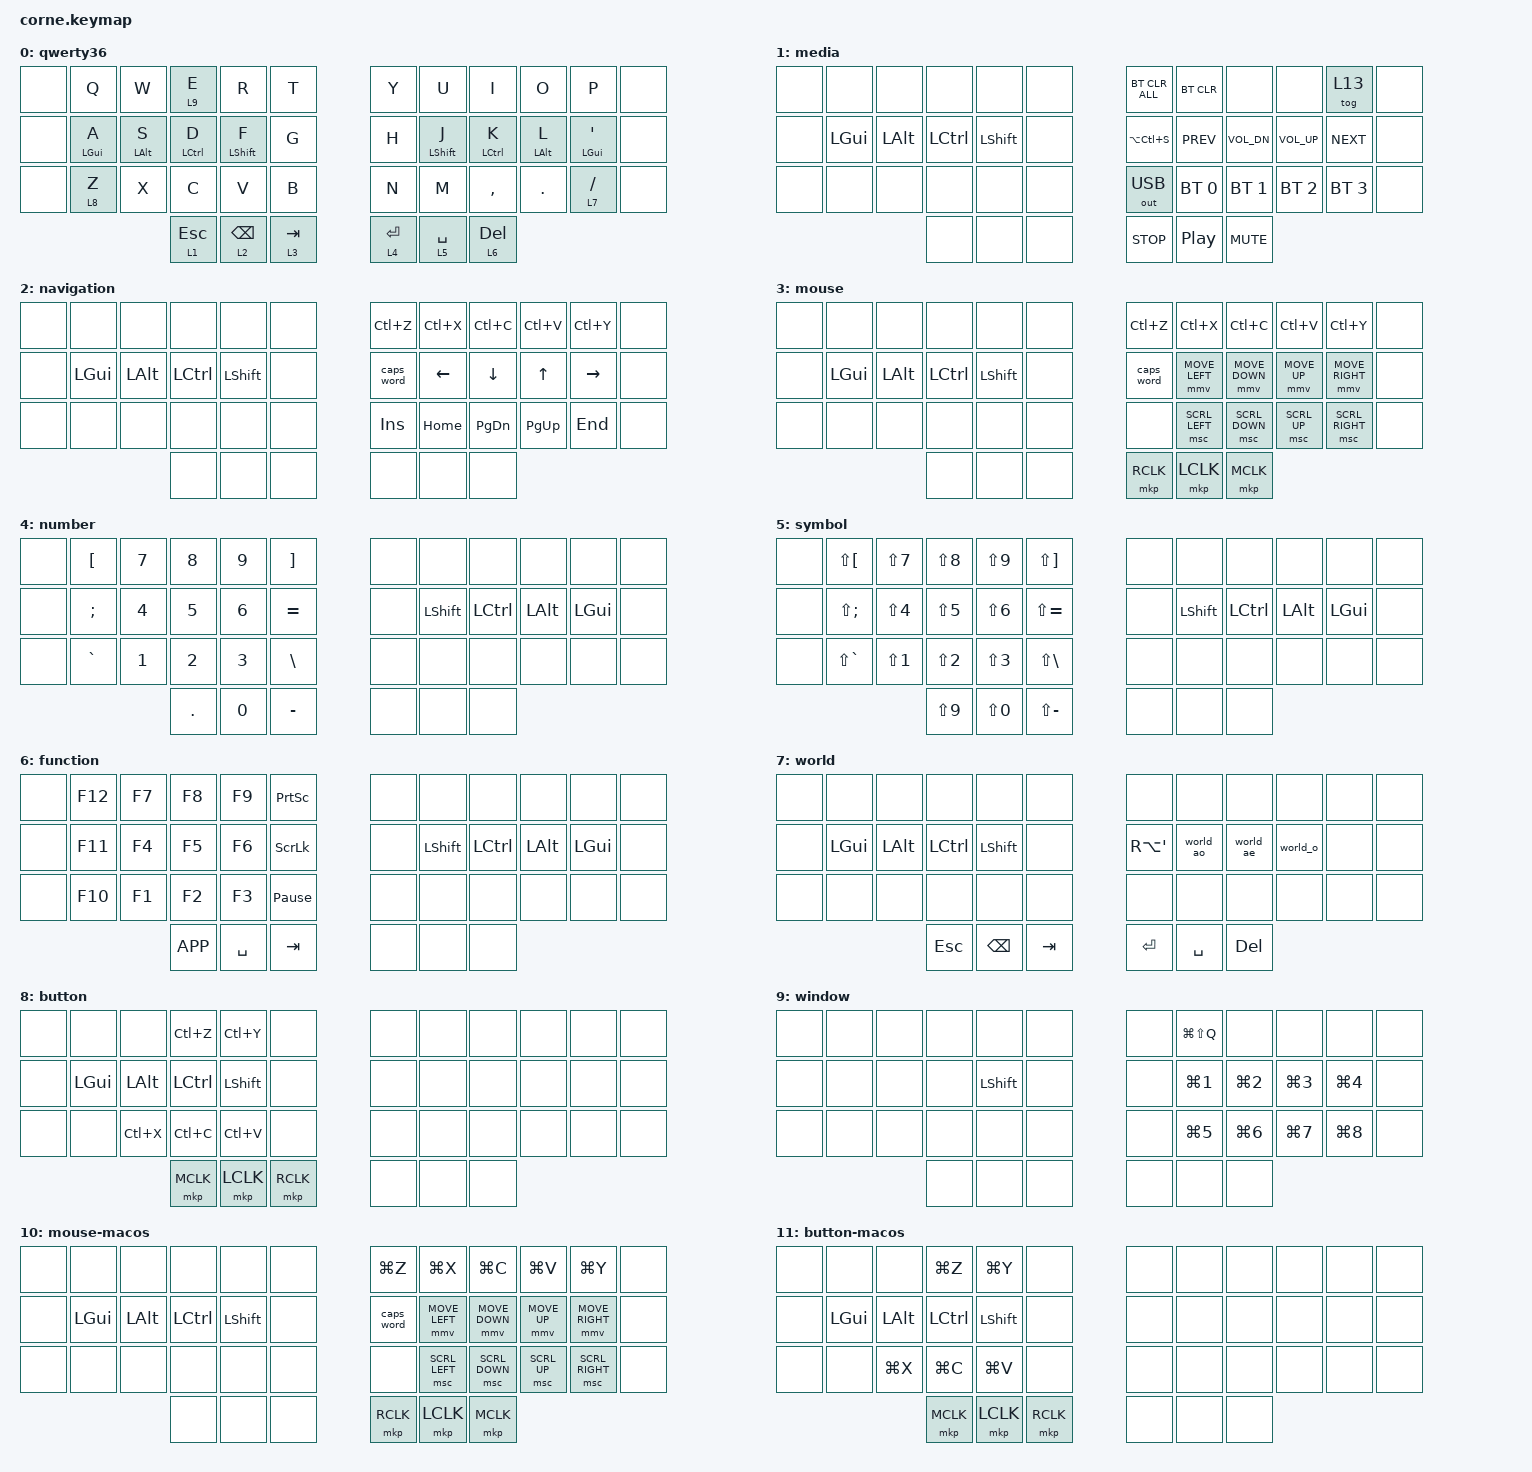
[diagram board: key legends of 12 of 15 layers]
/*
 * Copyright (c) 2020 The ZMK Contributors
 *
 * SPDX-License-Identifier: MIT
 */

#include <behaviors.dtsi>
#include <dt-bindings/zmk/bt.h>
#include <dt-bindings/zmk/keys.h>
#include <dt-bindings/zmk/outputs.h>
#include <dt-bindings/zmk/pointing.h>

&mt { tapping-term-ms = <150>; };

/ {
    macros {
        world_ao_base: world_ao {
            compatible = "zmk,behavior-macro";
            #binding-cells = <0>;
            bindings =
                <&macro_press>,
                <&kp RALT>,
                <&macro_tap>,
                <&kp ASTRK &kp A>,
                <&macro_release>,
                <&kp RALT>;

            label = "WORLD_AO";
            wait-ms = <1>;
            tap-ms = <1>;
        };

        world_ao_lsft: world_ao_lsft {
            compatible = "zmk,behavior-macro";
            #binding-cells = <0>;
            bindings =
                <&macro_press>,
                <&kp RALT>,
                <&macro_tap>,
                <&kp ASTRK &kp LS(A)>,
                <&macro_release>,
                <&kp RALT>;

            label = "WORLD_AO_LSFT";
            wait-ms = <1>;
            tap-ms = <1>;
        };

        world_ae_base: world_ae_base {
            compatible = "zmk,behavior-macro";
            #binding-cells = <0>;
            bindings =
                <&macro_press>,
                <&kp RALT>,
                <&macro_tap>,
                <&kp DOUBLE_QUOTES &kp A>,
                <&macro_release>,
                <&kp RALT>;

            label = "WORLD_AE_BASE";
            wait-ms = <1>;
            tap-ms = <1>;
        };

        world_ae_lsft: world_ae_lsft {
            compatible = "zmk,behavior-macro";
            #binding-cells = <0>;
            bindings =
                <&macro_press>,
                <&kp RALT>,
                <&macro_tap>,
                <&kp DOUBLE_QUOTES &kp LS(A)>,
                <&macro_release>,
                <&kp RALT>;

            label = "WORLD_AE_LSFT";
            wait-ms = <1>;
            tap-ms = <1>;
        };

        world_o_base: world_o_base {
            compatible = "zmk,behavior-macro";
            #binding-cells = <0>;
            bindings =
                <&macro_press>,
                <&kp RALT>,
                <&macro_tap>,
                <&kp DOUBLE_QUOTES &kp O>,
                <&macro_release>,
                <&kp RALT>;

            label = "WORLD_O_BASE";
            wait-ms = <1>;
            tap-ms = <1>;
        };

        world_o_lsft: world_o_lsft {
            compatible = "zmk,behavior-macro";
            #binding-cells = <0>;
            bindings =
                <&macro_press>,
                <&kp RALT>,
                <&macro_tap>,
                <&kp DOUBLE_QUOTES &kp LS(O)>,
                <&macro_release>,
                <&kp RALT>;

            label = "WORLD_O_LSFT";
            wait-ms = <1>;
            tap-ms = <1>;
        };

        world_ao_macos_base: world_ao_macos_base {
            compatible = "zmk,behavior-macro";
            #binding-cells = <0>;
            bindings =
                <&macro_tap>,
                <&kp RA(A)>;

            label = "WORLD_AO_MACOS_BASE";
            wait-ms = <5>;
            tap-ms = <5>;
        };

        world_ao_macos_lsft: world_ao_macos_lsft {
            compatible = "zmk,behavior-macro";
            #binding-cells = <0>;
            bindings =
                <&macro_tap>,
                <&kp RA(LS(A))>;

            label = "WORLD_AO_MACOS_LSFT";
            wait-ms = <5>;
            tap-ms = <5>;
        };

        world_ae_macos_base: world_ae_macos_base {
            compatible = "zmk,behavior-macro";
            #binding-cells = <0>;
            bindings =
                <&macro_tap>,
                <&kp RA(U) &kp A>;

            label = "WORLD_AE_MACOS_BASE";
            wait-ms = <5>;
            tap-ms = <5>;
        };

        world_ae_macos_lsft: world_ae_macos_lsft {
            compatible = "zmk,behavior-macro";
            #binding-cells = <0>;
            bindings =
                <&macro_tap>,
                <&kp RA(U) &kp LS(A)>;

            label = "WORLD_AE_MACOS_LSFT";
            wait-ms = <5>;
            tap-ms = <5>;
        };

        world_o_macos_base: world_o_macos_base {
            compatible = "zmk,behavior-macro";
            #binding-cells = <0>;
            bindings =
                <&macro_tap>,
                <&kp RA(U) &kp O>;

            label = "WORLD_O_MACOS_BASE";
            wait-ms = <5>;
            tap-ms = <5>;
        };

        world_o_macos_lsft: world_o_macos_lsft {
            compatible = "zmk,behavior-macro";
            #binding-cells = <0>;
            bindings =
                <&macro_tap>,
                <&kp RA(U) &kp LS(O)>;

            label = "WORLD_O_MACOS_LSFT";
            wait-ms = <5>;
            tap-ms = <5>;
        };
    };

    behaviors {
        world_ao: world_ao {
            compatible = "zmk,behavior-mod-morph";
            label = "WORLD_AO";
            bindings = <&world_ao_base>, <&world_ao_lsft>;

            #binding-cells = <0>;
            mods = <(MOD_LSFT)>;
        };

        world_ae: world_ae {
            compatible = "zmk,behavior-mod-morph";
            label = "WORLD_AE";
            bindings = <&world_ae_base>, <&world_ae_lsft>;

            #binding-cells = <0>;
            mods = <(MOD_LSFT)>;
        };

        world_o: world_o {
            compatible = "zmk,behavior-mod-morph";
            label = "WORLD_O";
            bindings = <&world_o_base>, <&world_o_lsft>;

            #binding-cells = <0>;
            mods = <(MOD_LSFT)>;
        };

        world_ao_macos: world_ao_macos {
            compatible = "zmk,behavior-mod-morph";
            label = "WORLD_AO_MACOS";
            bindings = <&world_ao_macos_base>, <&world_ao_macos_lsft>;

            #binding-cells = <0>;
            mods = <(MOD_LSFT)>;
        };

        world_ae_macos: world_ae_macos {
            compatible = "zmk,behavior-mod-morph";
            label = "WORLD_AE_MACOS";
            bindings = <&world_ae_macos_base>, <&world_ae_macos_lsft>;

            #binding-cells = <0>;
            mods = <(MOD_LSFT)>;
        };

        world_o_macos: world_o_macos {
            compatible = "zmk,behavior-mod-morph";
            label = "WORLD_O_MACOS";
            bindings = <&world_o_macos_base>, <&world_o_macos_lsft>;

            #binding-cells = <0>;
            mods = <(MOD_LSFT)>;
        };
    };

    conditional_layers {
        compatible = "zmk,conditional-layers";

        mouses_macos {
            if-layers = <3 13>;
            then-layer = <10>;
        };

        buttons_macos {
            if-layers = <8 13>;
            then-layer = <11>;
        };

        windows_macos {
            if-layers = <9 13>;
            then-layer = <12>;
        };

        world_macos {
            if-layers = <7 13>;
            then-layer = <14>;
        };
    };

    keymap {
        compatible = "zmk,keymap";

        qwerty36 {
            // -----------------------------------------------------------------------------------------
            // |  TAB |  Q  |  W  |  E  |  R  |  T  |   |  Y  |  U   |  I  |  O  |  P  | BSPC |
            // | CTRL |  A  |  S  |  D  |  F  |  G  |   |  H  |  J   |  K  |  L  |  ;  |  '   |
            // | SHFT |  Z  |  X  |  C  |  V  |  B  |   |  N  |  M   |  ,  |  .  |  /  | ESC  |
            //                    | GUI | LWR | SPC |   | ENT | RSE  | ALT |

            bindings = <
&none  &kp Q       &kp W           &lt 9 E       &kp R            &kp T        &kp Y        &kp U        &kp I         &kp O       &kp P                  &none
&none  &mt LGUI A  &mt LEFT_ALT S  &mt LCTRL D   &mt LSHFT F      &kp G        &kp H        &mt LSHFT J  &mt LCTRL K   &mt LALT L  &mt LGUI SINGLE_QUOTE  &none
&none  &lt 8 Z     &kp X           &kp C         &kp V            &kp B        &kp N        &kp M        &kp COMMA     &kp DOT     &lt 7 SLASH            &none
                                   &lt 1 ESCAPE  &lt 2 BACKSPACE  &lt 3 TAB    &lt 4 ENTER  &lt 5 SPACE  &lt 6 DELETE
            >;
        };

        media {
            bindings = <
&none  &none     &none     &none      &none      &none    &bt BT_CLR_ALL  &bt BT_CLR    &none         &none         &tog 13       &none
&none  &kp LGUI  &kp LALT  &kp LCTRL  &kp LSHFT  &none    &kp LA(LC(S))   &kp C_PREV    &kp C_VOL_DN  &kp C_VOL_UP  &kp C_NEXT    &none
&none  &none     &none     &none      &none      &none    &out OUT_USB    &bt BT_SEL 0  &bt BT_SEL 1  &bt BT_SEL 2  &bt BT_SEL 3  &none
                           &none      &none      &none    &kp C_STOP      &kp C_PP      &kp C_MUTE
            >;
        };

        navigation {
            bindings = <
&none  &none     &none     &none      &none      &none    &kp LC(Z)   &kp LC(X)  &kp LC(C)      &kp LC(V)    &kp LC(Y)  &none
&none  &kp LGUI  &kp LALT  &kp LCTRL  &kp LSHFT  &none    &caps_word  &kp LEFT   &kp DOWN       &kp UP       &kp RIGHT  &none
&none  &none     &none     &none      &none      &none    &kp INSERT  &kp HOME   &kp PAGE_DOWN  &kp PAGE_UP  &kp END    &none
                           &none      &none      &none    &none       &none      &none
            >;
        };

        mouse {
            bindings = <
&none  &none     &none     &none      &none      &none    &kp LC(Z)   &kp LC(X)       &kp LC(C)       &kp LC(V)     &kp LC(Y)        &none
&none  &kp LGUI  &kp LALT  &kp LCTRL  &kp LSHFT  &none    &caps_word  &mmv MOVE_LEFT  &mmv MOVE_DOWN  &mmv MOVE_UP  &mmv MOVE_RIGHT  &none
&none  &none     &none     &none      &none      &none    &none       &msc SCRL_LEFT  &msc SCRL_DOWN  &msc SCRL_UP  &msc SCRL_RIGHT  &none
                           &none      &none      &none    &mkp RCLK   &mkp LCLK       &mkp MCLK
            >;
        };

        number {
            bindings = <
&none  &kp LEFT_BRACKET  &kp N7  &kp N8   &kp N9  &kp RIGHT_BRACKET    &none  &none      &none      &none     &none     &none
&none  &kp SEMI          &kp N4  &kp N5   &kp N6  &kp EQUAL            &none  &kp LSHFT  &kp LCTRL  &kp LALT  &kp LGUI  &none
&none  &kp GRAVE         &kp N1  &kp N2   &kp N3  &kp BACKSLASH        &none  &none      &none      &none     &none     &none
                                 &kp DOT  &kp N0  &kp MINUS            &none  &none      &none
            >;
        };

        symbol {
            bindings = <
&none  &kp LS(LEFT_BRACKET)  &kp LS(N7)  &kp LS(N8)  &kp LS(N9)        &kp LS(RIGHT_BRACKET)    &none  &none      &none      &none     &none     &none
&none  &kp LS(SEMI)          &kp LS(N4)  &kp LS(N5)  &kp LS(NUMBER_6)  &kp LS(EQUAL)            &none  &kp LSHFT  &kp LCTRL  &kp LALT  &kp LGUI  &none
&none  &kp LS(GRAVE)         &kp LS(N1)  &kp LS(N2)  &kp LS(N3)        &kp LS(BACKSLASH)        &none  &none      &none      &none     &none     &none
                                         &kp LS(N9)  &kp LS(N0)        &kp LS(MINUS)            &none  &none      &none
            >;
        };

        function {
            bindings = <
&none  &kp F12  &kp F7  &kp F8     &kp F9     &kp PRINTSCREEN    &none  &none      &none      &none     &none     &none
&none  &kp F11  &kp F4  &kp F5     &kp F6     &kp SCROLLLOCK     &none  &kp LSHFT  &kp LCTRL  &kp LALT  &kp LGUI  &none
&none  &kp F10  &kp F1  &kp F2     &kp F3     &kp PAUSE_BREAK    &none  &none      &none      &none     &none     &none
                        &kp K_APP  &kp SPACE  &kp TAB            &none  &none      &none
            >;
        };

        world {
            bindings = <
&none  &none     &none     &none      &none      &none      &none         &none      &none       &none     &none  &none
&none  &kp LGUI  &kp LALT  &kp LCTRL  &kp LSHFT  &none      &kp RA(APOS)  &world_ao  &world_ae   &world_o  &none  &none
&none  &none     &none     &none      &none      &none      &none         &none      &none       &none     &none  &none
                           &kp ESC    &kp BSPC   &kp TAB    &kp ENTER     &kp SPACE  &kp DELETE
            >;
        };

        button {
            bindings = <
&none  &none     &none      &kp LC(Z)  &kp LC(Y)  &none        &none  &none  &none  &none  &none  &none
&none  &kp LGUI  &kp LALT   &kp LCTRL  &kp LSHFT  &none        &none  &none  &none  &none  &none  &none
&none  &none     &kp LC(X)  &kp LC(C)  &kp LC(V)  &none        &none  &none  &none  &none  &none  &none
                            &mkp MCLK  &mkp LCLK  &mkp RCLK    &none  &none  &none
            >;
        };

        window {
            bindings = <
&none  &none  &none  &none  &none      &none    &none  &kp LG(LS(Q))  &none       &none       &none       &none
&none  &none  &none  &none  &kp LSHFT  &none    &none  &kp LG(N1)     &kp LG(N2)  &kp LG(N3)  &kp LG(N4)  &none
&none  &none  &none  &none  &none      &none    &none  &kp LG(N5)     &kp LG(N6)  &kp LG(N7)  &kp LG(N8)  &none
                     &none  &none      &none    &none  &none          &none
            >;
        };

        mouse-macos {
            bindings = <
&none  &none     &none     &none      &none      &none    &kp LG(Z)   &kp LG(X)       &kp LG(C)       &kp LG(V)     &kp LG(Y)        &none
&none  &kp LGUI  &kp LALT  &kp LCTRL  &kp LSHFT  &none    &caps_word  &mmv MOVE_LEFT  &mmv MOVE_DOWN  &mmv MOVE_UP  &mmv MOVE_RIGHT  &none
&none  &none     &none     &none      &none      &none    &none       &msc SCRL_LEFT  &msc SCRL_DOWN  &msc SCRL_UP  &msc SCRL_RIGHT  &none
                           &none      &none      &none    &mkp RCLK   &mkp LCLK       &mkp MCLK
            >;
        };

        button-macos {
            bindings = <
&none  &none     &none      &kp LG(Z)  &kp LG(Y)  &none        &none  &none  &none  &none  &none  &none
&none  &kp LGUI  &kp LALT   &kp LCTRL  &kp LSHFT  &none        &none  &none  &none  &none  &none  &none
&none  &none     &kp LG(X)  &kp LG(C)  &kp LG(V)  &none        &none  &none  &none  &none  &none  &none
                            &mkp MCLK  &mkp LCLK  &mkp RCLK    &none  &none  &none
            >;
        };

        window-macos {
            bindings = <
&none  &none  &none  &none  &none      &none    &none  &kp LS(LA(Q))  &none       &none       &none       &none
&none  &none  &none  &none  &kp LSHFT  &none    &none  &kp LA(N1)     &kp LA(N2)  &kp LA(N3)  &kp LA(N4)  &none
&none  &none  &none  &none  &none      &none    &none  &kp LA(N5)     &kp LA(N6)  &kp LA(N7)  &kp LA(N8)  &none
                     &none  &none      &none    &none  &none          &none
            >;
        };

        os-macos {
            bindings = <
&trans  &trans  &trans  &trans  &trans  &trans    &trans  &trans  &trans  &trans  &trans  &trans
&trans  &trans  &trans  &trans  &trans  &trans    &trans  &trans  &trans  &trans  &trans  &trans
&trans  &trans  &trans  &trans  &trans  &trans    &trans  &trans  &trans  &trans  &trans  &trans
                        &trans  &trans  &trans    &trans  &trans  &trans
            >;
        };

        world-macos {
            bindings = <
&none  &none     &none     &none      &none      &none      &none         &none            &none            &none           &none  &none
&none  &kp LGUI  &kp LALT  &kp LCTRL  &kp LSHFT  &none      &kp RA(APOS)  &world_ao_macos  &world_ae_macos  &world_o_macos  &none  &none
&none  &none     &none     &none      &none      &none      &none         &none            &none            &none           &none  &none
                           &kp ESC    &kp BSPC   &kp TAB    &kp ENTER     &kp SPACE        &kp DELETE
            >;
        };
    };
};
